# APM32F40x register map
File version: 1.0
CPU: CM4 r1p0, little endian, no MPU, no FPU, 3 interrupt priority bits
Registers are 32-bit, read-write, reset 0x0 unless marked. A register's access mark holds for its fields unless they carry their own. Offsets are from the block's base; [hi:lo] are bit positions; {n}, {i} and the like mark numbered series; 'fields as' and 'values as' point back to an identical list.

## OTG_HS1_DEVICE — USB on the go high speed
Base 0x40040800
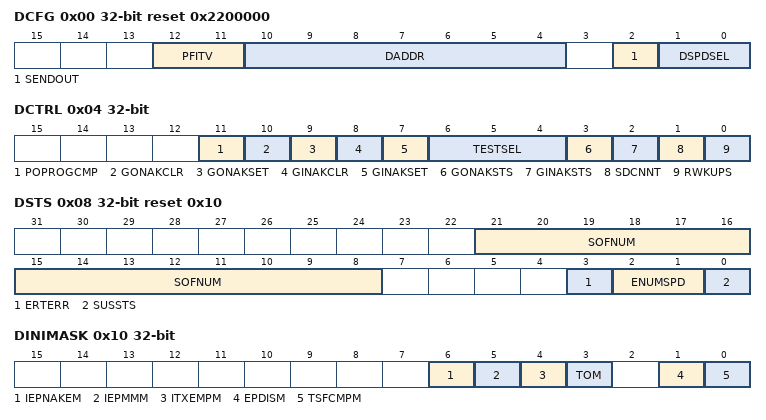
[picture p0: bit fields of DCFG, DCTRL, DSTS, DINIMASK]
0x00 DCFG reset 0x2200000 — OTG_HS device configuration register
  [12:11] PFITV — Periodic (micro)frame interval
  [10:4] DADDR — Device address
  [2] SENDOUT — Nonzero-length status OUT handshake
  [1:0] DSPDSEL — Device speed
0x04 DCTRL access per field — OTG_HS device control register
  [11] POPROGCMP rw — Power-on programming done
  [10] GONAKCLR wo — Clear global OUT NAK
  [9] GONAKSET wo — Set global OUT NAK
  [8] GINAKCLR wo — Clear global IN NAK
  [7] GINAKSET wo — Set global IN NAK
  [6:4] TESTSEL rw — Test control
  [3] GONAKSTS ro — Global OUT NAK status
  [2] GINAKSTS ro — Global IN NAK status
  [1] SDCNNT rw — Soft disconnect
  [0] RWKUPS rw — Remote wakeup signaling
0x08 DSTS ro reset 0x10 — OTG_HS device status register
  [21:8] SOFNUM — Frame number of the received SOF
  [3] ERTERR — Erratic error
  [2:1] ENUMSPD — Enumerated speed
  [0] SUSSTS — Suspend status
0x10 DINIMASK — OTG_HS device IN endpoint common interrupt mask register
  [6] IEPNAKEM — IN endpoint NAK effective mask
  [5] IEPMMM — IN token received with EP mismatch mask
  [4] ITXEMPM — IN token received when TxFIFO empty mask
  [3] TOM — Timeout condition mask (nonisochronous endpoints)
  [1] EPDISM — Endpoint disabled interrupt mask
  [0] TSFCMPM — Transfer completed interrupt mask
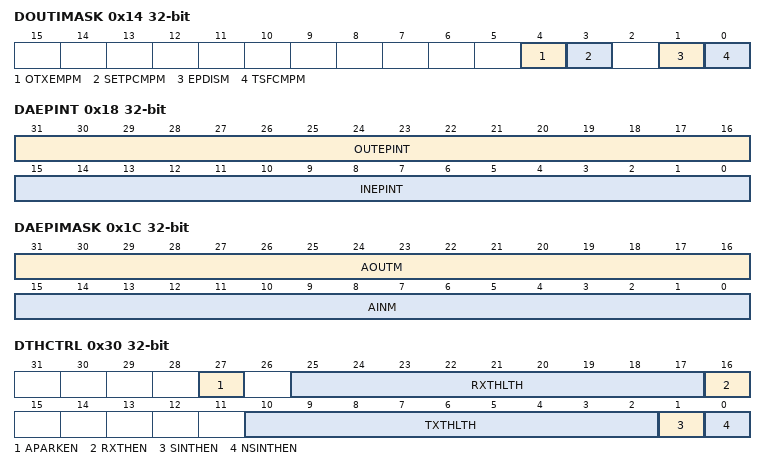
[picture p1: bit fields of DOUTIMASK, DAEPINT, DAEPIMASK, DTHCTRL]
0x14 DOUTIMASK — OTG_HS device OUT endpoint common interrupt mask register
  [4] OTXEMPM — OUT token received when endpoint disabled mask
  [3] SETPCMPM — SETUP phase done mask
  [1] EPDISM — Endpoint disabled interrupt mask
  [0] TSFCMPM — Transfer completed interrupt mask
0x18 DAEPINT ro — OTG_HS device all endpoints interrupt register
  [31:16] OUTEPINT — OUT endpoint interrupt bits
  [15:0] INEPINT — IN endpoint interrupt bits
0x1C DAEPIMASK — OTG_HS all endpoints interrupt mask register
  [31:16] AOUTM — OUT EP interrupt mask bits
  [15:0] AINM — IN EP interrupt mask bits
0x28 DVBUSDTIM reset 0x17D7 — OTG_HS device VBUS discharge time register
  [15:0] VBUSDTIM — Device VBUS discharge time
0x2C DVBUSPTIM reset 0x5B8 — OTG_HS device VBUS pulsing time register
  [11:0] VBUSPTIM — Device VBUS pulsing time
0x30 DTHCTRL — OTG_HS Device threshold control register
  [27] APARKEN — Arbiter parking enable
  [25:17] RXTHLTH — Receive threshold length
  [16] RXTHEN — Receive threshold enable
  [10:2] TXTHLTH — Transmit threshold length
  [1] SINTHEN — ISO IN endpoint threshold enable
  [0] NSINTHEN — Nonisochronous IN endpoints threshold enable
0x34 DIEIMASK — OTG_HS device IN endpoint FIFO empty interrupt mask register
  [15:0] INEM — IN EP Tx FIFO empty interrupt mask bits
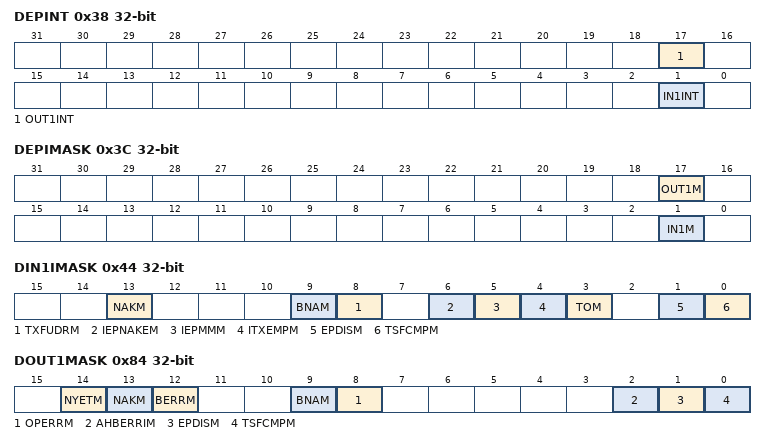
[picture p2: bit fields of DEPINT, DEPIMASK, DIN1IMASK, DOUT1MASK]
0x38 DEPINT — OTG_HS device each endpoint interrupt register
  [17] OUT1INT — OUT endpoint 1 interrupt bit
  [1] IN1INT — IN endpoint 1interrupt bit
0x3C DEPIMASK — OTG_HS device each endpoint interrupt register mask
  [17] OUT1M — OUT Endpoint 1 interrupt mask bit
  [1] IN1M — IN Endpoint 1 interrupt mask bit
0x44 DIN1IMASK — OTG_HS device each in endpoint-1 interrupt register
  [13] NAKM — NAK interrupt mask
  [9] BNAM — BNA interrupt mask
  [8] TXFUDRM — FIFO underrun mask
  [6] IEPNAKEM — IN endpoint NAK effective mask
  [5] IEPMMM — IN token received with EP mismatch mask
  [4] ITXEMPM — IN token received when TxFIFO empty mask
  [3] TOM — Timeout condition mask (nonisochronous endpoints)
  [1] EPDISM — Endpoint disabled interrupt mask
  [0] TSFCMPM — Transfer completed interrupt mask
0x84 DOUT1MASK — OTG_HS device each OUT endpoint-1 interrupt register
  [14] NYETM — NYET Interrupt Mask
  [13] NAKM — NAK Interrupt Mask
  [12] BERRM — Babble Error Interrupt Mask
  [9] BNAM — BNA Interrput Mask
  [8] OPERRM — OUT Packet Error Interrupt Mask
  [2] AHBERRIM — AHB Error Interrupt Mask
  [1] EPDISM — Endpoint disabled interrupt mask
  [0] TSFCMPM — Transfer completed interrupt mask
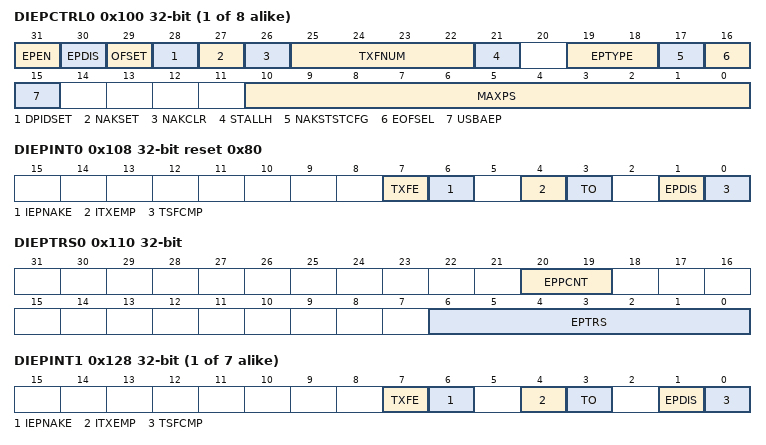
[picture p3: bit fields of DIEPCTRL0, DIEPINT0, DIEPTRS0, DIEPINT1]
{0x100+0x20*i} DIEPCTRL{i} access per field (i=0..7) — OTG device endpoint-{i} control register
  [31] EPEN rw — Endpoint enable
  [30] EPDIS rw — Endpoint disable
  [29] OFSET wo — Set odd frame
  [28] DPIDSET wo — Set DATA0 PID
  [27] NAKSET wo — Set NAK
  [26] NAKCLR wo — Clear NAK
  [25:22] TXFNUM rw — TxFIFO number
  [21] STALLH rw — STALL handshake
  [19:18] EPTYPE rw — Endpoint type
  [17] NAKSTSTCFG ro — NAK status
  [16] EOFSEL ro — Even/odd frame
  [15] USBAEP rw — USB active endpoint
  [10:0] MAXPS rw — Maximum packet size
0x108 DIEPINT0 access per field reset 0x80 — OTG device endpoint-0 interrupt register
  [7] TXFE ro — Transmit FIFO empty
  [6] IEPNAKE rw — IN endpoint NAK effective
  [4] ITXEMP rw — IN token received when TxFIFO is empty
  [3] TO rw — Timeout condition
  [1] EPDIS rw — Endpoint disabled interrupt
  [0] TSFCMP rw — Transfer completed interrupt
0x110 DIEPTRS0 — OTG_HS device IN endpoint 0 transfer size register
  [20:19] EPPCNT — Packet count
  [6:0] EPTRS — Transfer size
{0xF4+0x20*i} DIEPDMA_DOEPDMA{i} (i=1..5) — OTG_HS device endpoint-{i} DMA address register
  [31:0] DMAADDR — DMA address
{0x118+0x20*i} DITXFSTS{i} ro (i=0..5) — OTG_HS device IN endpoint transmit FIFO status register
  [15:0] INEPTXFSASEL — IN endpoint TxFIFO space avail
{0x108+0x20*i} DIEPINT{i} access per field (i=1..7) — OTG device endpoint-{i} interrupt register
  fields as DIEPINT0
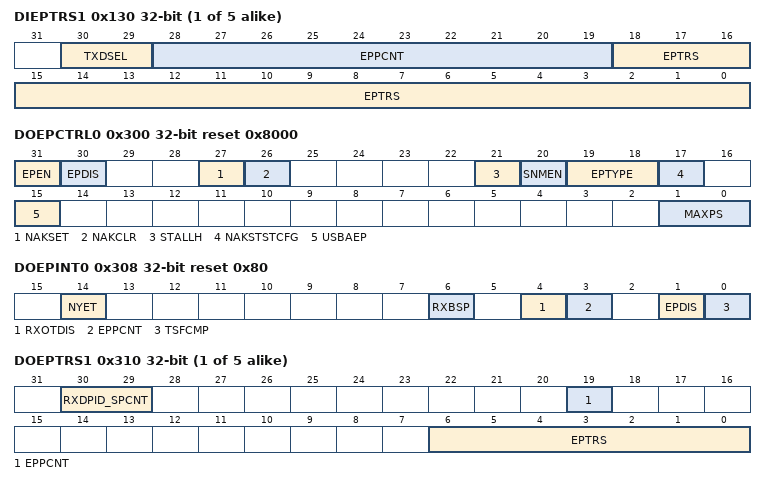
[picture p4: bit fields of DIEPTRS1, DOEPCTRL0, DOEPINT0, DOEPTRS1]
{0x110+0x20*i} DIEPTRS{i} (i=1..5) — OTG_HS device endpoint transfer size register
  [30:29] TXDSEL — Multi count
  [28:19] EPPCNT — Packet count
  [18:0] EPTRS — Transfer size
0x300 DOEPCTRL0 access per field reset 0x8000 — OTG_HS device control OUT endpoint 0 control register
  [31] EPEN wo — Endpoint enable
  [30] EPDIS ro — Endpoint disable
  [27] NAKSET wo — Set NAK
  [26] NAKCLR wo — Clear NAK
  [21] STALLH rw — STALL handshake
  [20] SNMEN rw — Snoop mode
  [19:18] EPTYPE ro — Endpoint type
  [17] NAKSTSTCFG ro — NAK status
  [15] USBAEP ro — USB active endpoint
  [1:0] MAXPS ro — Maximum packet size
0x308 DOEPINT0 reset 0x80 — OTG_HS device endpoint-0 interrupt register
  [14] NYET — NYET interrupt
  [6] RXBSP — Back-to-back SETUP packets received
  [4] RXOTDIS — OUT token received when endpoint disabled
  [3] EPPCNT — SETUP phase done
  [1] EPDIS — Endpoint disabled interrupt
  [0] TSFCMP — Transfer completed interrupt
{0x2F0+0x20*i} DOEPTRS{i} (i=1..5) — OTG_HS device endpoint-{i} transfer size register
  [30:29] RXDPID_SPCNT — SETUP packet count
  [19] EPPCNT — Packet count
  [6:0] EPTRS — Transfer size
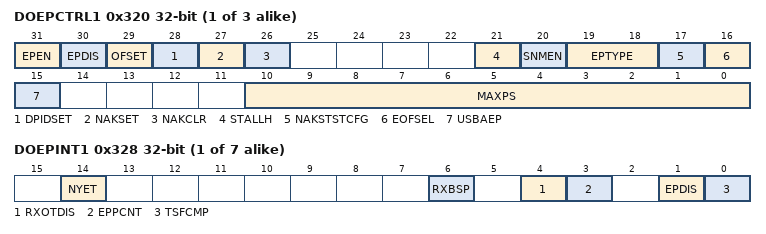
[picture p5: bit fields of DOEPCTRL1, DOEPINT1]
{0x300+0x20*i} DOEPCTRL{i} access per field (i=1..3) — OTG device endpoint-{i} control register
  [31] EPEN rw — Endpoint enable
  [30] EPDIS rw — Endpoint disable
  [29] OFSET wo — Set odd frame
  [28] DPIDSET wo — Set DATA0 PID/Set even frame
  [27] NAKSET wo — Set NAK
  [26] NAKCLR wo — Clear NAK
  [21] STALLH rw — STALL handshake
  [20] SNMEN rw — Snoop mode
  [19:18] EPTYPE rw — Endpoint type
  [17] NAKSTSTCFG ro — NAK status
  [16] EOFSEL ro — Even odd frame/Endpoint data PID
  [15] USBAEP rw — USB active endpoint
  [10:0] MAXPS rw — Maximum packet size
{0x308+0x20*i} DOEPINT{i} (i=1..7) — OTG_HS device endpoint-{i} interrupt register
  fields as DOEPINT0
